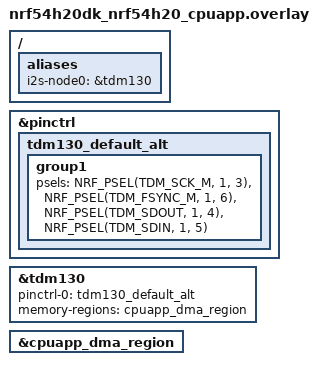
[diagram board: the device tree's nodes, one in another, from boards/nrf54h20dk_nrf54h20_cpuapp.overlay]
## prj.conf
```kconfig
CONFIG_I2S=y
CONFIG_ZTEST=y

#CONFIG_TEST_USERSPACE=y
#CONFIG_DEBUG=y
#CONFIG_NO_OPTIMIZATIONS=y
CONFIG_MAIN_STACK_SIZE=4096
CONFIG_ZTEST_STACK_SIZE=4096
CONFIG_IDLE_STACK_SIZE=1024
CONFIG_ISR_STACK_SIZE=2048
CONFIG_NRF_REGTOOL_VERBOSITY=3
CONFIG_CLOCK_CONTROL=y
```

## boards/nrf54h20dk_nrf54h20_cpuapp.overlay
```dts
/*
 * Copyright (c) 2024 Nordic Semiconductor ASA
 *
 * SPDX-License-Identifier: Apache-2.0
 */

/* i2s-node0 is the transmitter/receiver */

/ {
	aliases {
		i2s-node0 = &tdm130;
	};
};

&pinctrl {
	tdm130_default_alt: tdm130_default_alt {
		group1 {
			psels = <NRF_PSEL(TDM_SCK_M, 1, 3)>,
				<NRF_PSEL(TDM_FSYNC_M, 1, 6)>,
				<NRF_PSEL(TDM_SDOUT, 1, 4)>,
				<NRF_PSEL(TDM_SDIN, 1, 5)>;
		};
	};
};

&tdm130 {
	status = "okay";
	pinctrl-0 = <&tdm130_default_alt>;
	pinctrl-names = "default";
	memory-regions = <&cpuapp_dma_region>;
};

&cpuapp_dma_region {
    status = "okay";
};
```

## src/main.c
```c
/*
 * Copyright (c) 2017 comsuisse AG
 *
 * SPDX-License-Identifier: Apache-2.0
 */


#include <zephyr/kernel.h>
#include <zephyr/ztest.h>
#include <zephyr/device.h>
#include "i2s_api_test.h"

ZTEST_DMEM const struct device *dev_i2s_rx =
	DEVICE_DT_GET_OR_NULL(I2S_DEV_NODE_RX);
ZTEST_DMEM const struct device *dev_i2s_tx =
	DEVICE_DT_GET_OR_NULL(I2S_DEV_NODE_TX);
ZTEST_DMEM const struct device *dev_i2s =
	DEVICE_DT_GET_OR_NULL(I2S_DEV_NODE_RX);
ZTEST_DMEM bool dir_both_supported;

static void *setup(void)
{
	k_thread_access_grant(k_current_get(),
			      &rx_mem_slab, &tx_mem_slab);
	k_object_access_grant(dev_i2s_rx, k_current_get());
	k_object_access_grant(dev_i2s_tx, k_current_get());

	return NULL;
}

static void before(void *fixture)
{
	ARG_UNUSED(fixture);

	int ret;

	zassert_not_null(dev_i2s_rx, "RX device not found");
	zassert_true(device_is_ready(dev_i2s_rx),
		     "device %s is not ready", dev_i2s_rx->name);
	zassert_not_null(dev_i2s_tx, "TX device not found");
	zassert_true(device_is_ready(dev_i2s_tx),
		     "device %s is not ready", dev_i2s_tx->name);

	ret = configure_stream(dev_i2s_rx, I2S_DIR_RX);
	zassert_equal(ret, TC_PASS);

	ret = configure_stream(dev_i2s_tx, I2S_DIR_TX);
	zassert_equal(ret, TC_PASS);
}

static void before_dir_both(void *fixture)
{
//	static volatile bool wait = true;
//	while(wait);
	ARG_UNUSED(fixture);

	int ret;

	zassert_not_null(dev_i2s, "TX/RX device not found");
	zassert_true(device_is_ready(dev_i2s),
		     "device %s is not ready", dev_i2s->name);

	ret = configure_stream(dev_i2s, I2S_DIR_BOTH);
	zassert_equal(ret, TC_PASS);

	/* Check if the tested driver supports the I2S_DIR_BOTH value.
	 * Use the DROP trigger for this, as in the current state of the driver
	 * (READY, both TX and RX queues empty) it is actually a no-op.
	 */
	ret = i2s_trigger(dev_i2s, I2S_DIR_BOTH, I2S_TRIGGER_DROP);
	dir_both_supported = (ret == 0);

	if (IS_ENABLED(CONFIG_I2S_TEST_USE_I2S_DIR_BOTH)) {
		zassert_true(dir_both_supported,
			     "I2S_DIR_BOTH value is supposed to be supported.");
	}
}

ZTEST_SUITE(i2s_loopback, NULL, setup, before, NULL, NULL);
ZTEST_SUITE(i2s_states, NULL, setup, before, NULL, NULL);
ZTEST_SUITE(i2s_dir_both_states, NULL, setup, before_dir_both, NULL, NULL);
ZTEST_SUITE(i2s_dir_both_loopback, NULL, setup, before_dir_both, NULL, NULL);
ZTEST_SUITE(i2s_errors, NULL, setup, before, NULL, NULL);
```

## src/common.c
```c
/*
 * Copyright (c) 2017 comsuisse AG
 *
 * SPDX-License-Identifier: Apache-2.0
 */

#include <zephyr/kernel.h>
#include <zephyr/ztest.h>
#include <zephyr/drivers/i2s.h>
#include "i2s_api_test.h"

//K_MEM_SLAB_DEFINE(rx_mem_slab, BLOCK_SIZE, NUM_RX_BLOCKS, 32);
//K_MEM_SLAB_DEFINE(tx_mem_slab, BLOCK_SIZE, NUM_TX_BLOCKS, 32);

#include <zephyr/linker/devicetree_regions.h>

#define TDM(idx)                       DT_NODELABEL(tdm##idx)
#define TDM_PROP(idx, prop)            DT_PROP(TDM(idx), prop)
#define TDM_HAS_PROP(idx, prop)        DT_NODE_HAS_PROP(TDM(idx), prop)


#define TDM_MEMORY_SECTION(idx)                                               \
       COND_CODE_1(TDM_HAS_PROP(idx, memory_regions),                         \
               (__attribute__((__section__(LINKER_DT_NODE_REGION_NAME(        \
                       DT_PHANDLE(TDM(idx), memory_regions)))))),             \
               ())

#define BUFFER_MEM_REGION __attribute__((__section__("cpuapp_dma_region")))


struct k_mem_slab rx_mem_slab;
struct k_mem_slab tx_mem_slab;

static char __aligned(32) my_rx_slab_buffer[BLOCK_SIZE * NUM_RX_BLOCKS] TDM_MEMORY_SECTION(130);
static char __aligned(32) my_tx_slab_buffer[BLOCK_SIZE * NUM_TX_BLOCKS] TDM_MEMORY_SECTION(130);
static char tx_block[BLOCK_SIZE] TDM_MEMORY_SECTION(130);
static char rx_block[BLOCK_SIZE] TDM_MEMORY_SECTION(130);



/* The data_l represent a sine wave */
ZTEST_DMEM int16_t data_l[SAMPLE_NO] = {
	  6392,  12539,  18204,  23169,  27244,  30272,  32137,  32767,  32137,
	 30272,  27244,  23169,  18204,  12539,   6392,      0,  -6393, -12540,
	-18205, -23170, -27245, -30273, -32138, -32767, -32138, -30273, -27245,
	-23170, -18205, -12540,  -6393,     -1,
};

/* The data_r represent a sine wave with double the frequency of data_l */
ZTEST_DMEM int16_t data_r[SAMPLE_NO] = {
	 12539,  23169,  30272,  32767,  30272,  23169,  12539,      0, -12540,
	-23170, -30273, -32767, -30273, -23170, -12540,     -1,  12539,  23169,
	 30272,  32767,  30272,  23169,  12539,      0, -12540, -23170, -30273,
	-32767, -30273, -23170, -12540,     -1,
};

void test_slab_init(void)
{
	k_mem_slab_init(&rx_mem_slab, my_rx_slab_buffer, BLOCK_SIZE, NUM_RX_BLOCKS);
	k_mem_slab_init(&tx_mem_slab, my_tx_slab_buffer, BLOCK_SIZE, NUM_TX_BLOCKS);
}

static void fill_buf(int16_t *tx_block, int att)
{
	for (int i = 0; i < SAMPLE_NO; i++) {
		tx_block[2 * i] = data_l[i] >> att;
		tx_block[2 * i + 1] = data_r[i] >> att;
	}
}
static uint32_t cnt = 0;
static volatile bool wait = true;
static int verify_buf(int16_t *rx_block, int att)
{
	cnt ++;
	if(cnt > 1)
	{

	}
	int sample_no = SAMPLE_NO;

#if (CONFIG_I2S_TEST_ALLOWED_DATA_OFFSET > 0)
	static ZTEST_DMEM int offset = -1;

	if (offset < 0) {
		do {
			++offset;
			if (offset > CONFIG_I2S_TEST_ALLOWED_DATA_OFFSET) {
				while(wait);
				TC_PRINT("Allowed data offset exceeded\n");
				return -TC_FAIL;
			}
		} while (rx_block[2 * offset] != data_l[0] >> att);

		//TC_PRINT("Using data offset: %d\n", offset);
	}

	rx_block += 2 * offset;
	sample_no -= offset;
#endif

	for (int i = 0; i < sample_no; i++) {
		if (rx_block[2 * i] != data_l[i] >> att) {
			TC_PRINT("Error: att %d: data_l mismatch at position "
				 "%d, expected %d, actual %d\n",
				 att, i, data_l[i] >> att, rx_block[2 * i]);
			return -TC_FAIL;
		}
		if (rx_block[2 * i + 1] != data_r[i] >> att) {
			TC_PRINT("Error: att %d: data_r mismatch at position "
				 "%d, expected %d, actual %d\n",
				 att, i, data_r[i] >> att, rx_block[2 * i + 1]);
			return -TC_FAIL;
		}
	}

	return TC_PASS;
}

void fill_buf_const(int16_t *tx_block, int16_t val_l, int16_t val_r)
{
	for (int i = 0; i < SAMPLE_NO; i++) {
		tx_block[2 * i] = val_l;
		tx_block[2 * i + 1] = val_r;
	}
}

int verify_buf_const(int16_t *rx_block, int16_t val_l, int16_t val_r)
{
	for (int i = 0; i < SAMPLE_NO; i++) {
		if (rx_block[2 * i] != val_l) {
			TC_PRINT("Error: data_l mismatch at position "
				 "%d, expected %d, actual %d\n",
				 i, val_l, rx_block[2 * i]);
			return -TC_FAIL;
		}
		if (rx_block[2 * i + 1] != val_r) {
			TC_PRINT("Error: data_r mismatch at position "
				 "%d, expected %d, actual %d\n",
				 i, val_r, rx_block[2 * i + 1]);
			return -TC_FAIL;
		}
	}

	return TC_PASS;
}

static int tx_block_write_slab(const struct device *dev_i2s, int att, int err,
			       struct k_mem_slab *slab)
{
	//char tx_block[BLOCK_SIZE];
	int ret;

	fill_buf((uint16_t *)tx_block, att);
	ret = i2s_buf_write(dev_i2s, tx_block, BLOCK_SIZE);
	if (ret != err) {
		TC_PRINT("Error: i2s_write failed expected %d, actual %d\n",
			 err, ret);
		return -TC_FAIL;
	}

	return TC_PASS;
}

int tx_block_write(const struct device *dev_i2s, int att, int err)
{
	return tx_block_write_slab(dev_i2s, att, err, &tx_mem_slab);
}

static int rx_block_read_slab(const struct device *dev_i2s, int att,
			      struct k_mem_slab *slab)
{
	//char rx_block[BLOCK_SIZE];
	size_t rx_size;
	int ret;

	ret = i2s_buf_read(dev_i2s, rx_block, &rx_size);
	if (ret < 0 || rx_size != BLOCK_SIZE) {
		TC_PRINT("Error: Read failed\n");
		return -TC_FAIL;
	}
	ret = verify_buf((uint16_t *)rx_block, att);
	if (ret < 0) {
		TC_PRINT("Error: Verify failed\n");
		return -TC_FAIL;
	}

	return TC_PASS;
}

int rx_block_read(const struct device *dev_i2s, int att)
{
	return rx_block_read_slab(dev_i2s, att, &rx_mem_slab);
}

int configure_stream(const struct device *dev_i2s, enum i2s_dir dir)
{
	int ret;
	struct i2s_config i2s_cfg;

	i2s_cfg.word_size = 16U;
	i2s_cfg.channels = 2U;
	i2s_cfg.format = I2S_FMT_DATA_FORMAT_I2S;
	i2s_cfg.frame_clk_freq = FRAME_CLK_FREQ;
	i2s_cfg.block_size = BLOCK_SIZE;
	i2s_cfg.timeout = TIMEOUT;

	if (dir == I2S_DIR_TX) {
		/* Configure the Transmit port as Master */
		i2s_cfg.options = I2S_OPT_FRAME_CLK_MASTER
				| I2S_OPT_BIT_CLK_MASTER;
	} else if (dir == I2S_DIR_RX) {
		/* Configure the Receive port as Slave */
		i2s_cfg.options = I2S_OPT_FRAME_CLK_SLAVE
				| I2S_OPT_BIT_CLK_SLAVE;
	} else { /* dir == I2S_DIR_BOTH */
		i2s_cfg.options = I2S_OPT_FRAME_CLK_MASTER
				| I2S_OPT_BIT_CLK_MASTER;
	}

	if (!IS_ENABLED(CONFIG_I2S_TEST_USE_GPIO_LOOPBACK)) {
		i2s_cfg.options |= I2S_OPT_LOOPBACK;
	}

	if (dir == I2S_DIR_TX || dir == I2S_DIR_BOTH) {
		i2s_cfg.mem_slab = &tx_mem_slab;
		ret = i2s_configure(dev_i2s, I2S_DIR_TX, &i2s_cfg);
		if (ret < 0) {
			TC_PRINT("Failed to configure I2S TX stream (%d)\n",
				 ret);
			return -TC_FAIL;
		}
	}

	if (dir == I2S_DIR_RX || dir == I2S_DIR_BOTH) {
		i2s_cfg.mem_slab = &rx_mem_slab;
		ret = i2s_configure(dev_i2s, I2S_DIR_RX, &i2s_cfg);
		if (ret < 0) {
			TC_PRINT("Failed to configure I2S RX stream (%d)\n",
				 ret);
			return -TC_FAIL;
		}
	}

	return TC_PASS;
}
```

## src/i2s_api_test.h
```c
/*
 * Copyright (c) 2017 comsuisse AG
 * Copyright (c) 2018 Intel Corporation
 *
 * SPDX-License-Identifier: Apache-2.0
 */

#ifndef I2S_API_TEST_H
#define I2S_API_TEST_H

#include <zephyr/kernel.h>
#include <zephyr/drivers/i2s.h>

extern struct k_mem_slab rx_mem_slab;
extern struct k_mem_slab tx_mem_slab;

#define SAMPLE_NO	32
#define TIMEOUT		2000
#define FRAME_CLK_FREQ	1000

extern int16_t data_l[SAMPLE_NO];
extern int16_t data_r[SAMPLE_NO];

extern const struct device *dev_i2s_rx;
extern const struct device *dev_i2s_tx;
extern const struct device *dev_i2s;
extern bool dir_both_supported;

#define I2S_DEV_NODE_RX DT_ALIAS(i2s_node0)
#ifdef CONFIG_I2S_TEST_SEPARATE_DEVICES
#define I2S_DEV_NODE_TX DT_ALIAS(i2s_node1)
#else
#define I2S_DEV_NODE_TX DT_ALIAS(i2s_node0)
#endif
#define BLOCK_SIZE (2 * sizeof(data_l))

#define NUM_RX_BLOCKS	4
#define NUM_TX_BLOCKS	4

int tx_block_write(const struct device *dev_i2s, int att, int err);
int rx_block_read(const struct device *dev_i2s, int att);

void fill_buf_const(int16_t *tx_block, int16_t val_l, int16_t val_r);
int verify_buf_const(int16_t *rx_block, int16_t val_l, int16_t val_r);

int configure_stream(const struct device *dev_i2s, enum i2s_dir dir);

#endif
```

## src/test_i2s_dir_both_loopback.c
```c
/*
 * Copyright (c) 2017 comsuisse AG
 * Copyright (c) 2021 Nordic Semiconductor ASA
 *
 * SPDX-License-Identifier: Apache-2.0
 */

#include <zephyr/kernel.h>
#include <zephyr/ztest.h>
#include <zephyr/drivers/i2s.h>
#include "i2s_api_test.h"

/* The test cases here are copied from test_i2s_loopback.c and adapted for use
 * on devices that cannot independently start and stop the RX and TX streams
 * and require the use of the I2S_DIR_BOTH value for RX/TX transfers.
 */


#define TEST_I2S_TRANSFER_LONG_REPEAT_COUNT  100

/** @brief Long I2S transfer.
 *
 * - START trigger starts both the transmission and reception.
 * - Sending / receiving a long sequence of data returns success.
 * - DRAIN trigger empties the transmit queue and stops both streams.
 */
ZTEST_USER(i2s_dir_both_loopback, test_i2s_dir_both_transfer_long)
{
	extern void test_slab_init(void);
	test_slab_init();
	if (!dir_both_supported) {
		TC_PRINT("I2S_DIR_BOTH value is not supported.\n");
		ztest_test_skip();
		return;
	}

	int ret;

	//static volatile bool wait = true;
	//while(wait);
	/* Prefill TX queue */
	ret = tx_block_write(dev_i2s, 0, 0);
	zassert_equal(ret, TC_PASS);

	ret = i2s_trigger(dev_i2s, I2S_DIR_BOTH, I2S_TRIGGER_START);
	zassert_equal(ret, 0, "RX/TX START trigger failed\n");

	for (int i = 0; i < TEST_I2S_TRANSFER_LONG_REPEAT_COUNT; i++) {
		//printk("X%d\n", i);
		ret = tx_block_write(dev_i2s, 0, 0);
		zassert_equal(ret, TC_PASS);

		ret = rx_block_read(dev_i2s, 0);
		zassert_equal(ret, TC_PASS);
	}

	/* All data written, all but one data block read, flush TX queue
	 * and stop both streams.
	 */
	ret = i2s_trigger(dev_i2s, I2S_DIR_BOTH, I2S_TRIGGER_DRAIN);
	zassert_equal(ret, 0, "RX/TX DRAIN trigger failed");

	ret = rx_block_read(dev_i2s, 0);
	zassert_equal(ret, TC_PASS);

	/* TODO: Verify the interface is in READY state when i2s_state_get
	 * function is available.
	 */
}
```
